AUTOSAR XML (schema 00048)
package /MICROSAR/SBC/ComponentTypes
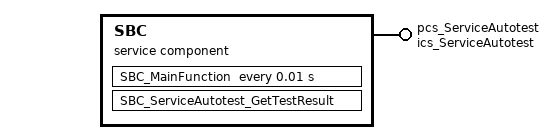
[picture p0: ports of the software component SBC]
  service sw component type SBC
    provide port pcs_ServiceAutotest: server-com-spec{operation=GetTestResult, queue-length=1}, provided-interface=ics_ServiceAutotest
    behavior SBC_InternalBehavior: data-type-mapping=DataTypeMappingSet_PP4G
      timing event TMT_SBC_MainFunction: start-on-event=SBC_MainFunction, period=0.01
      operation invoked event OIT_ics_ServiceAutotest_GetTestResult_ics_ServiceAutotest_GetTestResult: start-on-event=SBC_ServiceAutotest_GetTestResult, operation=pcs_ServiceAutotest.GetTestResult
      runnable SBC_MainFunction
      runnable SBC_ServiceAutotest_GetTestResult
  swc implementation SBC_Implementation: behavior=SBC_InternalBehavior
